# R7FA8M1AH register map
Vendor: Renesas; Series: RA8; File version: 1.2
CPU: CM85 r0p0, little endian, MPU, FPU, VTOR, 4 interrupt priority bits
Registers are 32-bit, read-write, reset 0x0 unless marked. A register's access mark holds for its fields unless they carry their own. Offsets are from the block's base; [hi:lo] are bit positions; {n}, {i} and the like mark numbered series; 'fields as' and 'values as' point back to an identical list.

## PFS — Pmn Pin Function Control Register
Base 0x40400800
Same registers: PFS_NS 0x50400800
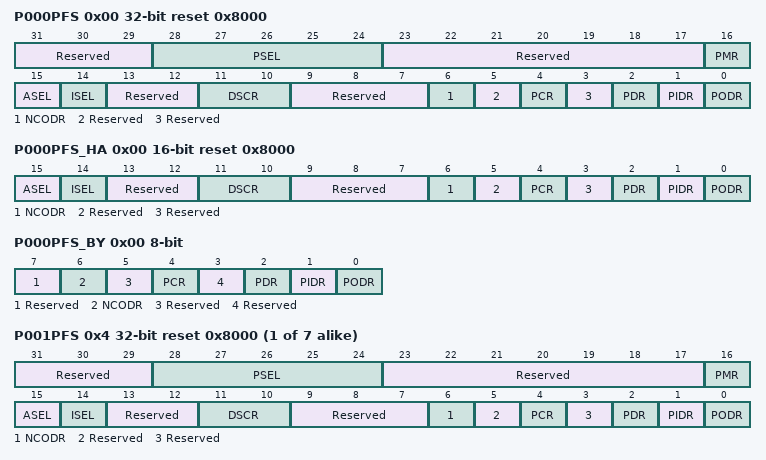
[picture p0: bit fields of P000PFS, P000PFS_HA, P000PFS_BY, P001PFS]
0x00 P000PFS reset 0x8000 (reset mask 0xFFFFFFFD) — P000 Pin Function Control Register
  [31:29] Reserved — These bits are read as 000. The write value should be 000.
  [28:24] PSEL — Port Function SelectThese bits select the peripheral function. For individual pin functions, see the MPC table
  [23:17] Reserved — These bits are read as 0000000. The write value should be 0000000.
  [16] PMR — Port Mode Control
    0=Uses the pin as a general I/O pin; 1=Uses the pin as an I/O port for peripheral functions
  [15] ASEL — Analog Input enable
    0=Used other than as analog pin; 1=Used as analog pin
  [14] ISEL — IRQ input enable
    0=Not used as IRQn input pin; 1=Used as IRQn input pin
  [13:12] Reserved — These bits are read as 00. The write value should be 00.
  [11:10] DSCR — Drive Strength Control Register
    0=Normal drive output; 1=Middle drive output; 2=Extra high drive; 3=High-drive output
  [9:7] Reserved — These bits are read as 000. The write value should be 000.
  [6] NCODR — N-Channel Open Drain Control
    0=CMOS output; 1=NMOS open-drain output
  [5] Reserved — This bit is read as 0. The write value should be 0.
  [4] PCR — Pull-up Control
    0=Disables an input pull-up; 1=Enables an input pull-up
  [3] Reserved — This bit is read as 0. The write value should be 0.
  [2] PDR — Port Direction
    0=Input (Functions as an input pin.); 1=Output (Functions as an output pin.)
  [1] PIDR ro — Port Input Data
    0=Low input; 1=High input
  [0] PODR — Port Output Data
    0=Low output; 1=High output
0x00 P000PFS_HA 16-bit reset 0x8000 (reset mask 0xFFFD) (alternate view of P000PFS) — P000 Pin Function Control Register
  [15] ASEL — Analog Input enable
    0=Used other than as analog pin; 1=Used as analog pin
  [14] ISEL — IRQ input enable
    0=Not used as IRQn input pin; 1=Used as IRQn input pin
  [13:12] Reserved — These bits are read as 00. The write value should be 00.
  [11:10] DSCR — Drive Strength Control Register
    values as P000PFS.DSCR
  [9:7] Reserved — These bits are read as 000. The write value should be 000.
  [6] NCODR — N-Channel Open Drain Control
    0=CMOS output; 1=NMOS open-drain output
  [5] Reserved — This bit is read as 0. The write value should be 0.
  [4] PCR — Pull-up Control
    0=Disables an input pull-up; 1=Enables an input pull-up
  [3] Reserved — This bit is read as 0. The write value should be 0.
  [2] PDR — Port Direction
    values as P000PFS.PDR
  [1] PIDR ro — Port Input Data
    0=Low input; 1=High input
  [0] PODR — Port Output Data
    0=Low output; 1=High output
0x00 P000PFS_BY 8-bit (reset mask 0xFD) (alternate view of P000PFS) — P000 Pin Function Control Register
  [7] Reserved — This bit is read as 0. The write value should be 0.
  [6] NCODR — N-Channel Open Drain Control
    0=CMOS output; 1=NMOS open-drain output
  [5] Reserved — This bit is read as 0. The write value should be 0.
  [4] PCR — Pull-up Control
    0=Disables an input pull-up; 1=Enables an input pull-up
  [3] Reserved — This bit is read as 0. The write value should be 0.
  [2] PDR — Port Direction
    values as P000PFS.PDR
  [1] PIDR ro — Port Input Data
    0=Low input; 1=High input
  [0] PODR — Port Output Data
    0=Low output; 1=High output
{0x0+4i} P00{i}PFS (i=1..7) reset 0x8000 (reset mask 0xFFFFFFFD) — P00{i} Pin Function Control Register
  fields as P000PFS
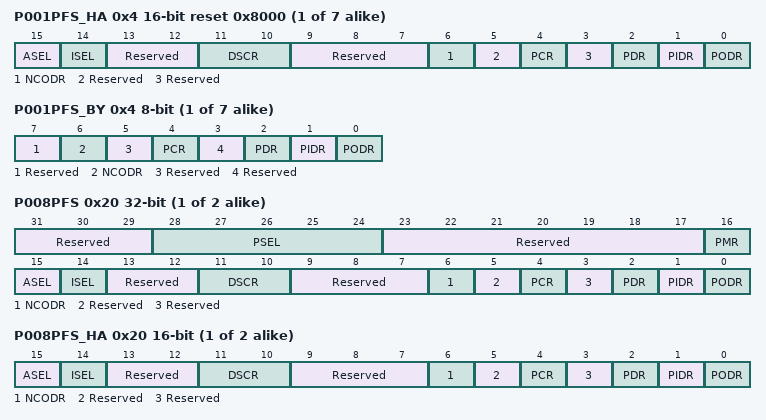
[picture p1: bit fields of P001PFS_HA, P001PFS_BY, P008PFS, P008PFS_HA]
{0x0+4i} P00{i}PFS_HA (i=1..7) 16-bit reset 0x8000 (reset mask 0xFFFD) (alternate view of P00{i}PFS) — P00{i} Pin Function Control Register
  fields as P000PFS_HA
{0x0+4i} P00{i}PFS_BY (i=1..7) 8-bit (reset mask 0xFD) (alternate view of P00{i}PFS) — P00{i} Pin Function Control Register
  fields as P000PFS_BY
{0x0+4i} P00{i}PFS (i=8..9) (reset mask 0xFFFFFFFD) — P00{i} Pin Function Control Register
  fields as P000PFS
{0x0+4i} P00{i}PFS_HA (i=8..9) 16-bit (reset mask 0xFFFD) (alternate view of P00{i}PFS) — P00{i} Pin Function Control Register
  fields as P000PFS_HA
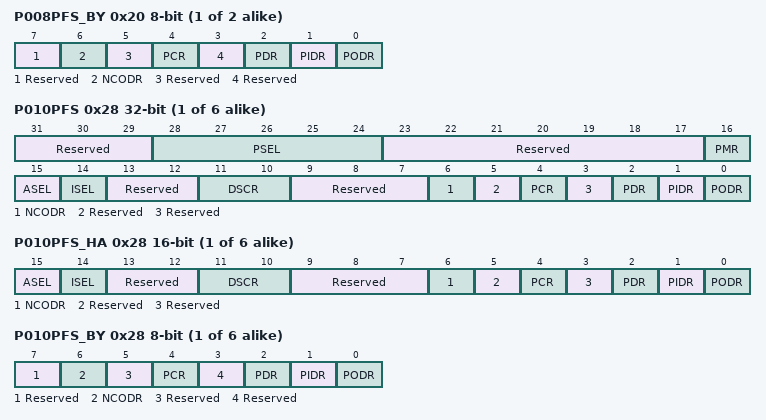
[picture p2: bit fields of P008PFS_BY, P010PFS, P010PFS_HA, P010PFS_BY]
{0x0+4i} P00{i}PFS_BY (i=8..9) 8-bit (reset mask 0xFD) (alternate view of P00{i}PFS) — P00{i} Pin Function Control Register
  fields as P000PFS_BY
{0x0+4i} P0{i}PFS (i=10..15) (reset mask 0xFFFFFFFD) — P0{i} Pin Function Control Register
  fields as P000PFS
{0x0+4i} P0{i}PFS_HA (i=10..15) 16-bit (reset mask 0xFFFD) — P0{i} Pin Function Control Register
  fields as P000PFS_HA
{0x0+4i} P0{i}PFS_BY (i=10..15) 8-bit (reset mask 0xFD) — P0{i} Pin Function Control Register
  fields as P000PFS_BY
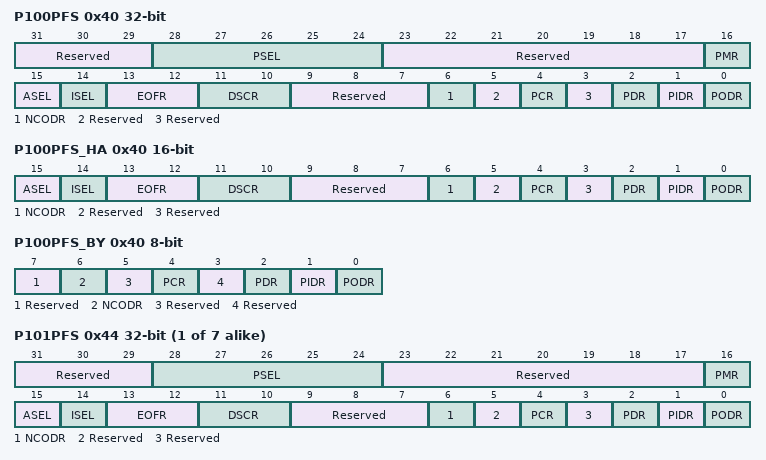
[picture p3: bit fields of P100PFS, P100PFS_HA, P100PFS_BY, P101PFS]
0x40 P100PFS (reset mask 0xFFFFFFFD) — P100 Pin Function Control Register
  [31:29] Reserved — These bits are read as 000. The write value should be 000.
  [28:24] PSEL — Port Function SelectThese bits select the peripheral function. For individual pin functions, see the MPC table
  [23:17] Reserved — These bits are read as 0000000. The write value should be 0000000.
  [16] PMR — Port Mode Control
    values as P000PFS.PMR
  [15] ASEL — Analog Input enable
    0=Used other than as analog pin; 1=Used as analog pin
  [14] ISEL — IRQ input enable
    0=Not used as IRQn input pin; 1=Used as IRQn input pin
  [13:12] EOFR — Event on Falling/Event on Rising
    0=No need to care; 1=Detect rising edge; 2=Detect falling edge; 3=Detect both edges
  [11:10] DSCR — Drive Strength Control Register
    values as P000PFS.DSCR
  [9:7] Reserved — These bits are read as 000. The write value should be 000.
  [6] NCODR — N-Channel Open Drain Control
    0=CMOS output; 1=NMOS open-drain output
  [5] Reserved — This bit is read as 0. The write value should be 0.
  [4] PCR — Pull-up Control
    0=Disables an input pull-up; 1=Enables an input pull-up
  [3] Reserved — This bit is read as 0. The write value should be 0.
  [2] PDR — Port Direction
    values as P000PFS.PDR
  [1] PIDR ro — Port Input Data
    0=Low input; 1=High input
  [0] PODR — Port Output Data
    0=Low output; 1=High output
0x40 P100PFS_HA 16-bit (reset mask 0xFFFD) — P100 Pin Function Control Register
  [15] ASEL — Analog Input enable
    0=Used other than as analog pin; 1=Used as analog pin
  [14] ISEL — IRQ input enable
    0=Not used as IRQn input pin; 1=Used as IRQn input pin
  [13:12] EOFR — Event on Falling/Event on Rising
    values as P100PFS.EOFR
  [11:10] DSCR — Drive Strength Control Register
    values as P000PFS.DSCR
  [9:7] Reserved — These bits are read as 000. The write value should be 000.
  [6] NCODR — N-Channel Open Drain Control
    0=CMOS output; 1=NMOS open-drain output
  [5] Reserved — This bit is read as 0. The write value should be 0.
  [4] PCR — Pull-up Control
    0=Disables an input pull-up; 1=Enables an input pull-up
  [3] Reserved — This bit is read as 0. The write value should be 0.
  [2] PDR — Port Direction
    values as P000PFS.PDR
  [1] PIDR ro — Port Input Data
    0=Low input; 1=High input
  [0] PODR — Port Output Data
    0=Low output; 1=High output
0x40 P100PFS_BY 8-bit (reset mask 0xFD) — P100 Pin Function Control Register
  fields as P000PFS_BY
{0x40+4i} P10{i}PFS (i=1..7) (reset mask 0xFFFFFFFD) (alternate view of P10{i}PFS) — P10{i} Pin Function Control Register
  fields as P100PFS
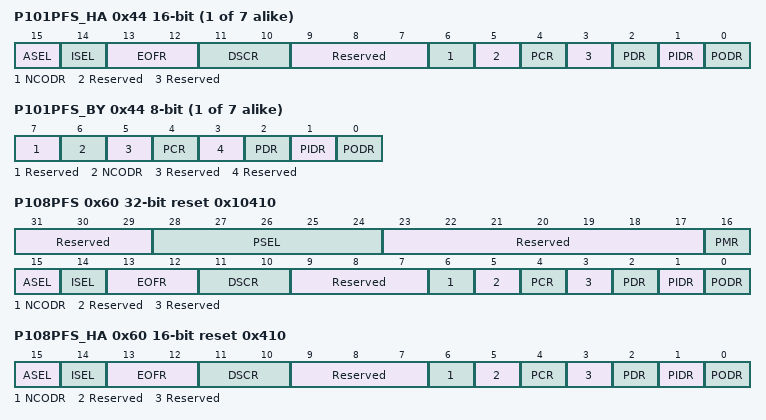
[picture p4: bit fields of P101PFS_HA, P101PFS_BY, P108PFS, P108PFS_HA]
{0x40+4i} P10{i}PFS_HA (i=1..7) 16-bit (reset mask 0xFFFD) (alternate view of P10{i}PFS) — P10{i} Pin Function Control Register
  fields as P100PFS_HA
{0x40+4i} P10{i}PFS_BY (i=1..7) 8-bit (reset mask 0xFD) (alternate view of P10{i}PFS) — P10{i} Pin Function Control Register
  fields as P000PFS_BY
0x60 P108PFS reset 0x10410 (reset mask 0xFFFFFFFD) — P108 Pin Function Control Register
  fields as P100PFS
0x60 P108PFS_HA 16-bit reset 0x410 (reset mask 0xFFFD) (alternate view of P108PFS) — P108 Pin Function Control Register
  fields as P100PFS_HA
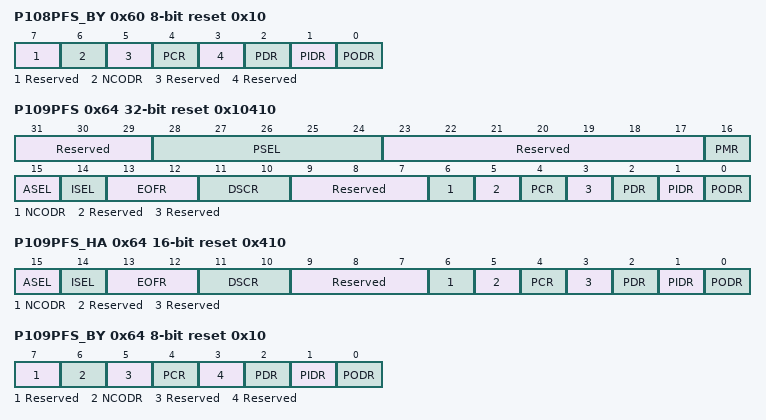
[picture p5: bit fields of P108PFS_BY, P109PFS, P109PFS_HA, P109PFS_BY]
0x60 P108PFS_BY 8-bit reset 0x10 (reset mask 0xFD) (alternate view of P108PFS) — P108 Pin Function Control Register
  fields as P000PFS_BY
0x64 P109PFS reset 0x10410 (reset mask 0xFFFFFFFD) — P109 Pin Function Control Register
  fields as P100PFS
0x64 P109PFS_HA 16-bit reset 0x410 (reset mask 0xFFFD) (alternate view of P109PFS) — P109 Pin Function Control Register
  fields as P100PFS_HA
0x64 P109PFS_BY 8-bit reset 0x10 (reset mask 0xFD) (alternate view of P109PFS) — P109 Pin Function Control Register
  fields as P000PFS_BY
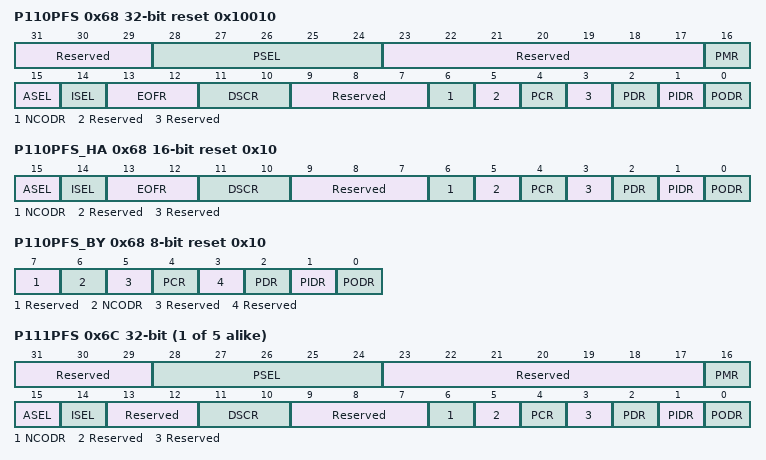
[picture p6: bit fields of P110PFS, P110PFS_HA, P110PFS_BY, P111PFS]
0x68 P110PFS reset 0x10010 (reset mask 0xFFFFFFFD) — P110 Pin Function Control Register
  fields as P100PFS
0x68 P110PFS_HA 16-bit reset 0x10 (reset mask 0xFFFD) (alternate view of P110PFS) — P110 Pin Function Control Register
  fields as P100PFS_HA
0x68 P110PFS_BY 8-bit reset 0x10 (reset mask 0xFD) (alternate view of P110PFS) — P110 Pin Function Control Register
  fields as P000PFS_BY
{0x40+4i} P1{i}PFS (i=11..15) (reset mask 0xFFFFFFFD) — P1{i} Pin Function Control Register
  fields as P000PFS
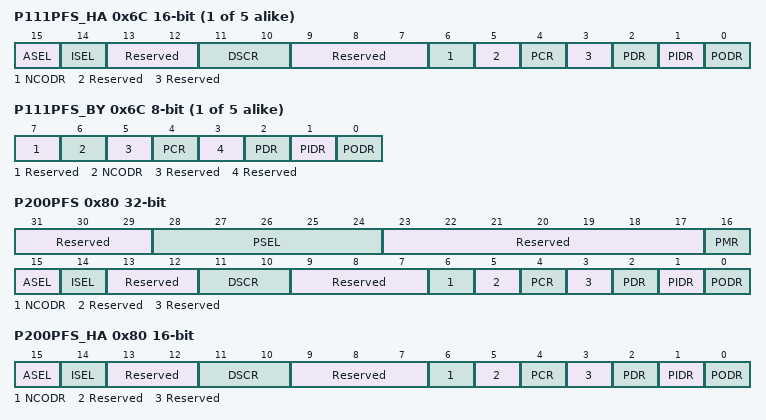
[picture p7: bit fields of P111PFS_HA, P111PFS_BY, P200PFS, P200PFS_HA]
{0x40+4i} P1{i}PFS_HA (i=11..15) 16-bit (reset mask 0xFFFD) (alternate view of P1{i}PFS) — P1{i} Pin Function Control Register
  fields as P000PFS_HA
{0x40+4i} P1{i}PFS_BY (i=11..15) 8-bit (reset mask 0xFD) (alternate view of P1{i}PFS) — P1{i} Pin Function Control Register
  fields as P000PFS_BY
0x80 P200PFS (reset mask 0xFFFFFFFD) — P200 Pin Function Control Register
  fields as P000PFS
0x80 P200PFS_HA 16-bit (reset mask 0xFFFD) (alternate view of P200PFS) — P200 Pin Function Control Register
  fields as P000PFS_HA
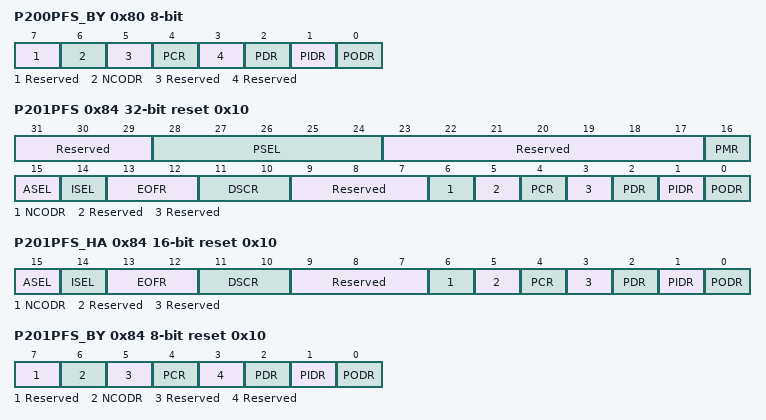
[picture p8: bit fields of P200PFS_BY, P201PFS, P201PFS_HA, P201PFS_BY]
0x80 P200PFS_BY 8-bit (reset mask 0xFD) (alternate view of P200PFS) — P200 Pin Function Control Register
  fields as P000PFS_BY
0x84 P201PFS reset 0x10 (reset mask 0xFFFFFFFD) — P201 Pin Function Control Register
  fields as P100PFS
0x84 P201PFS_HA 16-bit reset 0x10 (reset mask 0xFFFD) (alternate view of P201PFS) — P201 Pin Function Control Register
  fields as P100PFS_HA
0x84 P201PFS_BY 8-bit reset 0x10 (reset mask 0xFD) (alternate view of P201PFS) — P201 Pin Function Control Register
  fields as P000PFS_BY
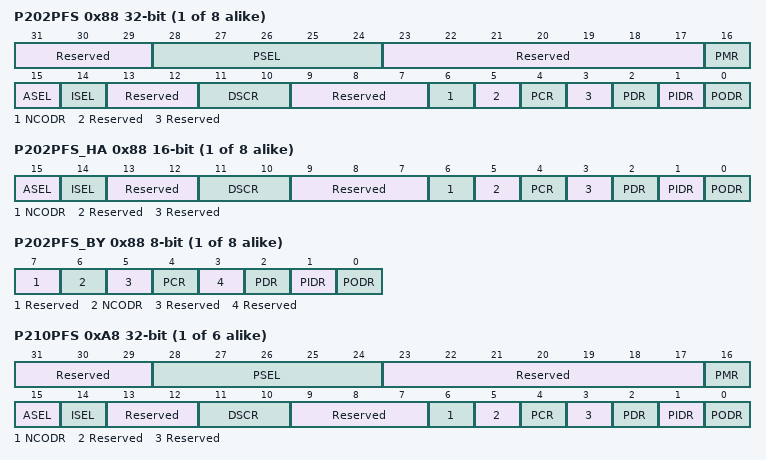
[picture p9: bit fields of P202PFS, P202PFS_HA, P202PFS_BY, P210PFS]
{0x80+4i} P20{i}PFS (i=2..9) (reset mask 0xFFFFFFFD) — P20{i} Pin Function Control Register
  fields as P000PFS
{0x80+4i} P20{i}PFS_HA (i=2..9) 16-bit (reset mask 0xFFFD) (alternate view of P20{i}PFS) — P20{i} Pin Function Control Register
  fields as P000PFS_HA
{0x80+4i} P20{i}PFS_BY (i=2..9) 8-bit (reset mask 0xFD) (alternate view of P20{i}PFS) — P20{i} Pin Function Control Register
  fields as P000PFS_BY
{0x80+4i} P2{i}PFS (i=10..15) (reset mask 0xFFFFFFFD) — P2{i} Pin Function Control Register
  fields as P000PFS
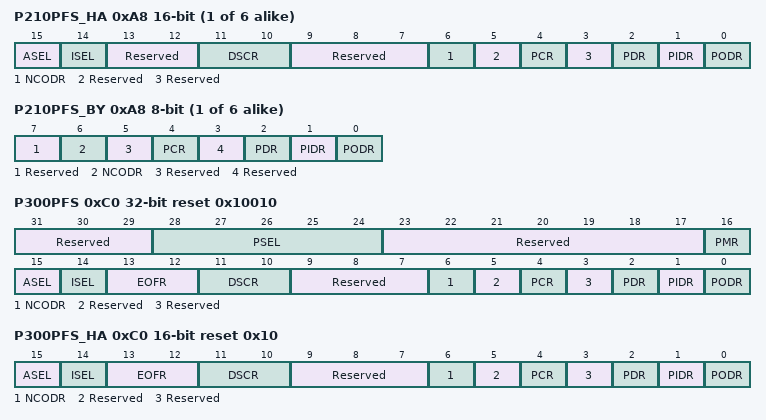
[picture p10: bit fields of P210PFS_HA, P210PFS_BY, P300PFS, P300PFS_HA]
{0x80+4i} P2{i}PFS_HA (i=10..15) 16-bit (reset mask 0xFFFD) (alternate view of P2{i}PFS) — P2{i} Pin Function Control Register
  fields as P000PFS_HA
{0x80+4i} P2{i}PFS_BY (i=10..15) 8-bit (reset mask 0xFD) (alternate view of P2{i}PFS) — P2{i} Pin Function Control Register
  fields as P000PFS_BY
0xC0 P300PFS reset 0x10010 (reset mask 0xFFFFFFFD) — P300 Pin Function Control Register
  fields as P100PFS
0xC0 P300PFS_HA 16-bit reset 0x10 (reset mask 0xFFFD) (alternate view of P300PFS) — P300 Pin Function Control Register
  fields as P100PFS_HA
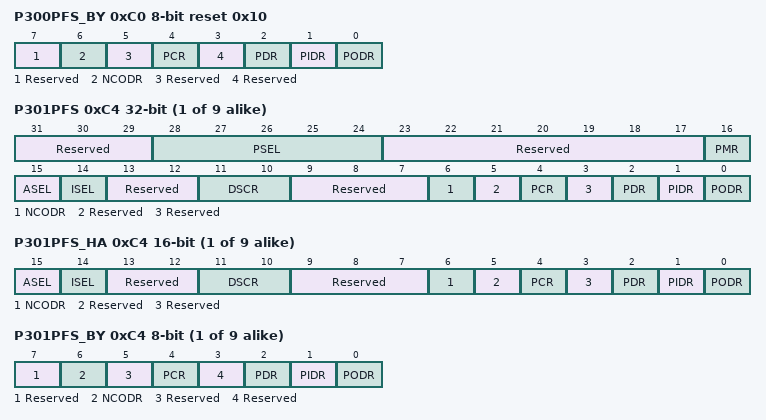
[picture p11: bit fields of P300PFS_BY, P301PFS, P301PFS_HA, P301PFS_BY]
0xC0 P300PFS_BY 8-bit reset 0x10 (reset mask 0xFD) (alternate view of P300PFS) — P300 Pin Function Control Register
  fields as P000PFS_BY
{0xC0+4i} P30{i}PFS (i=1..9) (reset mask 0xFFFFFFFD) — P30{i} Pin Function Control Register
  fields as P000PFS
{0xC0+4i} P30{i}PFS_HA (i=1..9) 16-bit (reset mask 0xFFFD) (alternate view of P30{i}PFS) — P30{i} Pin Function Control Register
  fields as P000PFS_HA
{0xC0+4i} P30{i}PFS_BY (i=1..9) 8-bit (reset mask 0xFD) (alternate view of P30{i}PFS) — P30{i} Pin Function Control Register
  fields as P000PFS_BY
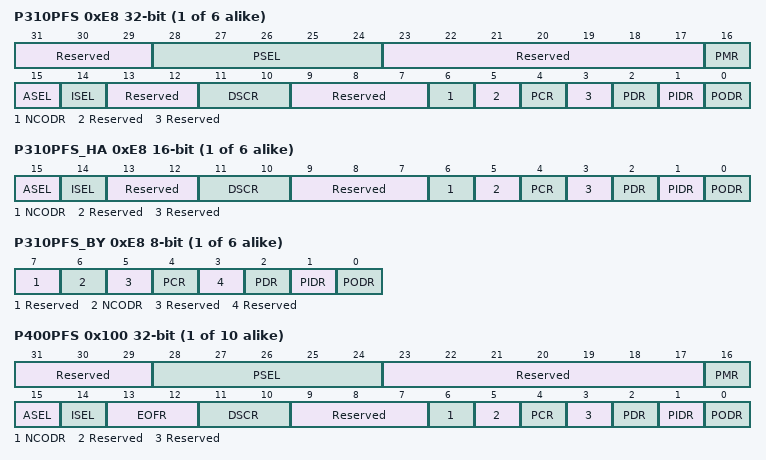
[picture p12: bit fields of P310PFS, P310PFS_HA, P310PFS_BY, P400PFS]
{0xC0+4i} P3{i}PFS (i=10..15) (reset mask 0xFFFFFFFD) — P3{i} Pin Function Control Register
  fields as P000PFS
{0xC0+4i} P3{i}PFS_HA (i=10..15) 16-bit (reset mask 0xFFFD) (alternate view of P3{i}PFS) — P30{i} Pin Function Control Register
  fields as P000PFS_HA
{0xC0+4i} P3{i}PFS_BY (i=10..15) 8-bit (reset mask 0xFD) (alternate view of P3{i}PFS) — P30{i} Pin Function Control Register
  fields as P000PFS_BY
{0x100+4i} P40{i}PFS (i=0..9) (reset mask 0xFFFFFFFD) — P40{i} Pin Function Control Register
  fields as P100PFS
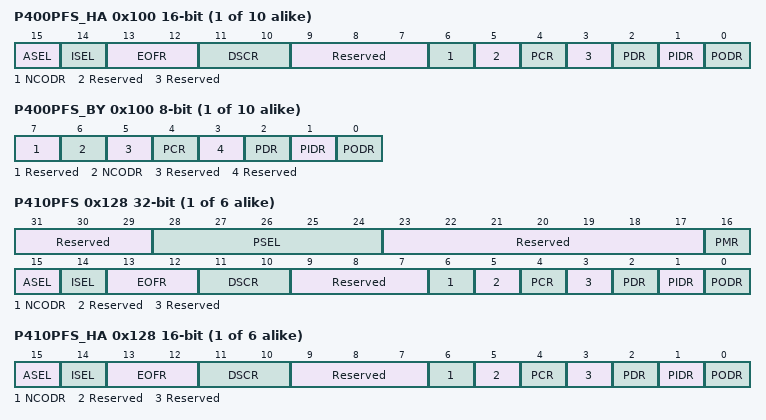
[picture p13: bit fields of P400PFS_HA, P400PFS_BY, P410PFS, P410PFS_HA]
{0x100+4i} P40{i}PFS_HA (i=0..9) 16-bit (reset mask 0xFFFD) (alternate view of P40{i}PFS) — P40{i} Pin Function Control Register
  fields as P100PFS_HA
{0x100+4i} P40{i}PFS_BY (i=0..9) 8-bit (reset mask 0xFD) (alternate view of P40{i}PFS) — P40{i} Pin Function Control Register
  fields as P000PFS_BY
{0x100+4i} P4{i}PFS (i=10..15) (reset mask 0xFFFFFFFD) — P4{i} Pin Function Control Register
  fields as P100PFS
{0x100+4i} P4{i}PFS_HA (i=10..15) 16-bit (reset mask 0xFFFD) (alternate view of P4{i}PFS) — P4{i} Pin Function Control Register
  fields as P100PFS_HA
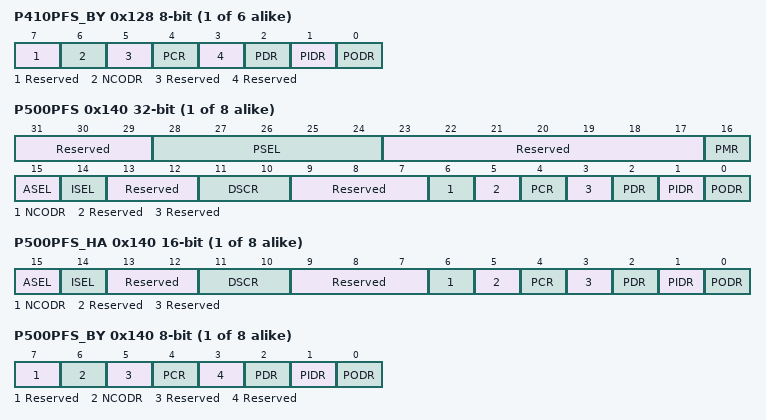
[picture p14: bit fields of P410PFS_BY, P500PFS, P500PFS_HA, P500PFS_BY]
{0x100+4i} P4{i}PFS_BY (i=10..15) 8-bit (reset mask 0xFD) (alternate view of P4{i}PFS) — P4{i} Pin Function Control Register
  fields as P000PFS_BY
{0x140+4i} P50{i}PFS (i=0..7) (reset mask 0xFFFFFFFD) — P50{i} Pin Function Control Register
  fields as P000PFS
{0x140+4i} P50{i}PFS_HA (i=0..7) 16-bit (reset mask 0xFFFD) (alternate view of P50{i}PFS) — P50{i} Pin Function Control Register
  fields as P000PFS_HA
{0x140+4i} P50{i}PFS_BY (i=0..7) 8-bit (reset mask 0xFD) (alternate view of P50{i}PFS) — P50{i} Pin Function Control Register
  fields as P000PFS_BY
{0x140+4i} P50{i}PFS (i=8..9) (reset mask 0xFFFFFFFD) — P50{i} Pin Function Control Register
  fields as P000PFS
{0x140+4i} P50{i}PFS_HA (i=8..9) 16-bit (reset mask 0xFFFD) (alternate view of P50{i}PFS) — P50{i} Pin Function Control Register
  fields as P000PFS_HA
{0x140+4i} P50{i}PFS_BY (i=8..9) 8-bit (reset mask 0xFD) (alternate view of P50{i}PFS) — P50{i} Pin Function Control Register
  fields as P000PFS_BY
{0x140+4i} P5{i}PFS (i=10..15) (reset mask 0xFFFFFFFD) — P5{i} Pin Function Control Register
  fields as P000PFS
{0x140+4i} P5{i}PFS_HA (i=10..15) 16-bit (reset mask 0xFFFD) (alternate view of P5{i}PFS) — P5{i} Pin Function Control Register
  fields as P000PFS_HA
{0x140+4i} P5{i}PFS_BY (i=10..15) 8-bit (reset mask 0xFD) (alternate view of P5{i}PFS) — P5{i} Pin Function Control Register
  fields as P000PFS_BY
{0x180+4i} P60{i}PFS (i=0..7) (reset mask 0xFFFFFFFD) — P60{i} Pin Function Control Register
  fields as P000PFS
{0x180+4i} P60{i}PFS_HA (i=0..7) 16-bit (reset mask 0xFFFD) (alternate view of P60{i}PFS) — P60{i} Pin Function Control Register
  fields as P000PFS_HA
{0x180+4i} P60{i}PFS_BY (i=0..7) 8-bit (reset mask 0xFD) (alternate view of P60{i}PFS) — P60{i} Pin Function Control Register
  fields as P000PFS_BY
{0x180+4i} P60{i}PFS (i=8..9) (reset mask 0xFFFFFFFD) — P60{i} Pin Function Control Register
  fields as P000PFS
{0x180+4i} P60{i}PFS_HA (i=8..9) 16-bit (reset mask 0xFFFD) (alternate view of P60{i}PFS) — P60{i} Pin Function Control Register
  fields as P000PFS_HA
{0x180+4i} P60{i}PFS_BY (i=8..9) 8-bit (reset mask 0xFD) (alternate view of P60{i}PFS) — P60{i} Pin Function Control Register
  fields as P000PFS_BY
{0x180+4i} P6{i}PFS (i=10..15) (reset mask 0xFFFFFFFD) — P6{i} Pin Function Control Register
  fields as P000PFS
{0x180+4i} P6{i}PFS_HA (i=10..15) 16-bit (reset mask 0xFFFD) (alternate view of P6{i}PFS) — P6{i} Pin Function Control Register
  fields as P000PFS_HA
{0x180+4i} P6{i}PFS_BY (i=10..15) 8-bit (reset mask 0xFD) (alternate view of P6{i}PFS) — P6{i} Pin Function Control Register
  fields as P000PFS_BY
{0x1C0+4i} P70{i}PFS (i=0..9) (reset mask 0xFFFFFFFD) — P70{i} Pin Function Control Register
  fields as P000PFS
{0x1C0+4i} P70{i}PFS_HA (i=0..9) 16-bit (reset mask 0xFFFD) (alternate view of P70{i}PFS) — P70{i} Pin Function Control Register
  fields as P000PFS_HA
{0x1C0+4i} P70{i}PFS_BY (i=0..9) 8-bit (reset mask 0xFD) (alternate view of P70{i}PFS) — P70{i} Pin Function Control Register
  fields as P000PFS_BY
{0x1C0+4i} P7{i}PFS (i=10..15) (reset mask 0xFFFFFFFD) — P7{i} Pin Function Control Register
  fields as P000PFS
{0x1C0+4i} P7{i}PFS_HA (i=10..15) 16-bit (reset mask 0xFFFD) (alternate view of P7{i}PFS) — P7{i} Pin Function Control Register
  fields as P000PFS_HA
{0x1C0+4i} P7{i}PFS_BY (i=10..15) 8-bit (reset mask 0xFD) (alternate view of P7{i}PFS) — P7{i} Pin Function Control Register
  fields as P000PFS_BY
{0x200+4i} P80{i}PFS (i=0..9) (reset mask 0xFFFFFFFD) — P80{i} Pin Function Control Register
  fields as P000PFS
{0x200+4i} P80{i}PFS_HA (i=0..9) 16-bit (reset mask 0xFFFD) (alternate view of P80{i}PFS) — P80{i} Pin Function Control Register
  fields as P000PFS_HA
{0x200+4i} P80{i}PFS_BY (i=0..9) 8-bit (reset mask 0xFD) (alternate view of P80{i}PFS) — P80{i} Pin Function Control Register
  fields as P000PFS_BY
{0x200+4i} P8{i}PFS (i=10..15) (reset mask 0xFFFFFFFD) — P8{i} Pin Function Control Register
  fields as P000PFS
{0x200+4i} P8{i}PFS_HA (i=10..15) 16-bit (reset mask 0xFFFD) (alternate view of P8{i}PFS) — P8{i} Pin Function Control Register
  fields as P000PFS_HA
{0x200+4i} P8{i}PFS_BY (i=10..15) 8-bit (reset mask 0xFD) (alternate view of P8{i}PFS) — P8{i} Pin Function Control Register
  fields as P000PFS_BY
{0x240+4i} P90{i}PFS (i=0..9) (reset mask 0xFFFFFFFD) — P90{i} Pin Function Control Register
  fields as P000PFS
{0x240+4i} P90{i}PFS_HA (i=0..9) 16-bit (reset mask 0xFFFD) (alternate view of P90{i}PFS) — P90{i} Pin Function Control Register
  fields as P000PFS_HA
{0x240+4i} P90{i}PFS_BY (i=0..9) 8-bit (reset mask 0xFD) (alternate view of P90{i}PFS) — P90{i} Pin Function Control Register
  fields as P000PFS_BY
{0x240+4i} P9{i}PFS (i=10..15) (reset mask 0xFFFFFFFD) — P9{i} Pin Function Control Register
  fields as P000PFS
{0x240+4i} P9{i}PFS_HA (i=10..15) 16-bit (reset mask 0xFFFD) (alternate view of P9{i}PFS) — P9{i} Pin Function Control Register
  fields as P000PFS_HA
{0x240+4i} P9{i}PFS_BY (i=10..15) 8-bit (reset mask 0xFD) (alternate view of P9{i}PFS) — P9{i} Pin Function Control Register
  fields as P000PFS_BY
{0x280+4i} PA0{i}PFS (i=0..9) (reset mask 0xFFFFFFFD) — PA0{i} Pin Function Control Register
  fields as P000PFS
{0x280+4i} PA0{i}PFS_HA (i=0..9) 16-bit (reset mask 0xFFFD) (alternate view of PA0{i}PFS) — PA0{i} Pin Function Control Register
  fields as P000PFS_HA
{0x280+4i} PA0{i}PFS_BY (i=0..9) 8-bit (reset mask 0xFD) (alternate view of PA0{i}PFS) — PA0{i} Pin Function Control Register
  fields as P000PFS_BY
{0x280+4i} PA{i}PFS (i=10..15) (reset mask 0xFFFFFFFD) — PA{i} Pin Function Control Register
  fields as P000PFS
{0x280+4i} PA{i}PFS_HA (i=10..15) 16-bit (reset mask 0xFFFD) (alternate view of PA{i}PFS) — PA{i} Pin Function Control Register
  fields as P000PFS_HA
{0x280+4i} PA{i}PFS_BY (i=10..15) 8-bit (reset mask 0xFD) (alternate view of PA{i}PFS) — PA{i} Pin Function Control Register
  fields as P000PFS_BY
{0x2C0+4i} PB0{i}PFS (i=0..9) (reset mask 0xFFFFFFFD) — PB0{i} Pin Function Control Register
  fields as P000PFS
{0x2C0+4i} PB0{i}PFS_HA (i=0..9) 16-bit (reset mask 0xFFFD) (alternate view of PB0{i}PFS) — PB0{i} Pin Function Control Register
  fields as P000PFS_HA
{0x2C0+4i} PB0{i}PFS_BY (i=0..9) 8-bit (reset mask 0xFD) (alternate view of PB0{i}PFS) — PB0{i} Pin Function Control Register
  fields as P000PFS_BY
{0x2C0+4i} PB{i}PFS (i=10..15) (reset mask 0xFFFFFFFD) — PB{i} Pin Function Control Register
  fields as P000PFS
{0x2C0+4i} PB{i}PFS_HA (i=10..15) 16-bit (reset mask 0xFFFD) (alternate view of PB{i}PFS) — PB{i} Pin Function Control Register
  fields as P000PFS_HA
{0x2C0+4i} PB{i}PFS_BY (i=10..15) 8-bit (reset mask 0xFD) (alternate view of PB{i}PFS) — PB{i} Pin Function Control Register
  fields as P000PFS_BY
0x500 PFENET 8-bit — Ethernet Control Register
  [7:5] Reserved — These bits are read as 000. The write value should be 000.
  [4] PHYMODE0 — Ethernet Mode Setting ch0
    0=RMII mode (ETHERC channel 0); 1=MII mode (ETHERC channel 0)
  [3:0] Reserved — These bits are read as 0000. The write value should be 0000.
0x50C PWPR_NS 8-bit reset 0x80 — NonSecure Write-Protect Register
  [7] B0WI — PFSWE Bit Write Disable
    0=Writing to the PFSWE bit is enabled; 1=Writing to the PFSWE bit is disabled
  [6] PFSWE — PFS Register Write Enable
    0=Writing to the PFS register is disabled; 1=Writing to the PFS register is enabled
  [5:0] Reserved — These bits are read as 000000. The write value should be 000000.
0x514 PWPR_S 8-bit reset 0x80 — Secure Write Protect Register
  [7] B0WI — PFSWE Bit Write Disable
    0=Enable writes the PFSWE bit; 1=Disable writes to the PFSWE bit
  [6] PFSWE — PmnPFS Register Write Enable
    0=Disable writes to the PmnPFS register; 1=Enable writes to the PmnPFS register
  [5:0] Reserved — These bits are read as 000000. The write value should be 000000.
0x520 PFI3C 8-bit — I3C Control Register
  [7:1] Reserved — These bits are read as 0000000. The write value should be 0000000.
  [0] I3CSLOPE0 — RI3C I3C Mode slope control setting bit
    0=I3C mode slope control disable; 1=I3C mode slope control enable
0x530 P0SAR 16-bit — Port Security Attribute register 0
  [all] fields
    0=Security Attribution is 0; 1=Security Attribution is 1
  [n] P{n:03}SA (n=0..15) — P{n:03} Security Attribute
0x534 P1SAR 16-bit — Port Security Attribute register 1
  [all] fields
    0=Security Attribution is 0; 1=Security Attribution is 1
  [n-100] P{n}SA (n=100..115) — P{n} Security Attribute
0x538 P2SAR 16-bit — Port Security Attribute register 1
  [all] fields
    0=Security Attribution is 0; 1=Security Attribution is 1
  [n-200] P{n}SA (n=200..215) — P{n} Security Attribute
0x53C P3SAR 16-bit — Port Security Attribute register 1
  [all] fields
    0=Security Attribution is 0; 1=Security Attribution is 1
  [n-300] P{n}SA (n=300..315) — P{n} Security Attribute
0x540 P4SAR 16-bit — Port Security Attribute register 1
  [all] fields
    0=Security Attribution is 0; 1=Security Attribution is 1
  [n-400] P{n}SA (n=400..415) — P{n} Security Attribute
0x544 P5SAR 16-bit — Port Security Attribute register 1
  [all] fields
    0=Security Attribution is 0; 1=Security Attribution is 1
  [n-500] P{n}SA (n=500..515) — P{n} Security Attribute
0x548 P6SAR 16-bit — Port Security Attribute register 1
  [all] fields
    0=Security Attribution is 0; 1=Security Attribution is 1
  [n-600] P{n}SA (n=600..615) — P{n} Security Attribute
0x54C P7SAR 16-bit — Port Security Attribute register 1
  [all] fields
    0=Security Attribution is 0; 1=Security Attribution is 1
  [n-700] P{n}SA (n=700..715) — P{n} Security Attribute
0x550 P8SAR 16-bit — Port Security Attribute register 1
  [all] fields
    0=Security Attribution is 0; 1=Security Attribution is 1
  [n-800] P{n}SA (n=800..815) — P{n} Security Attribute
0x554 P9SAR 16-bit — Port Security Attribute register 1
  [all] fields
    0=Security Attribution is 0; 1=Security Attribution is 1
  [n-900] P{n}SA (n=900..915) — P{n} Security Attribute
0x558 PASAR 16-bit — Port Security Attribute register 1
  [all] fields
    0=Security Attribution is 0; 1=Security Attribution is 1
  [n] PA{n:02}SA (n=0..15) — PA{n:02} Security Attribute
0x55C PBSAR 16-bit — Port Security Attribute register 1
  [all] fields
    0=Security Attribution is 0; 1=Security Attribution is 1
  [n] PB{n:02}SA (n=0..15) — PB{n:02} Security Attribute
0x560 PCSAR 16-bit — Port Security Attribute register 1
  fields as PBSAR
0x564 PDSAR 16-bit — Port Security Attribute register 1
  [all] fields
    0=Security Attribution is 0; 1=Security Attribution is 1
  [n] PC{n:02}SA (n=0..15) — PC{n:02} Security Attribute
0x568 PESAR 16-bit — Port Security Attribute register 1
  [all] fields
    0=Security Attribution is 0; 1=Security Attribution is 1
  [n] PD{n:02}SA (n=0..15) — PD{n:02} Security Attribute
0x56C PFSAR 16-bit — Port Security Attribute register 1
  [all] fields
    0=Security Attribution is 0; 1=Security Attribution is 1
  [n] PE{n:02}SA (n=0..15) — PE{n:02} Security Attribute
0x570 PGSAR 16-bit — Port Security Attribute register 1
  [all] fields
    0=Security Attribution is 0; 1=Security Attribution is 1
  [n] PG{n:02}SA (n=0..15) — PG{n:02} Security Attribute
